AUTOSAR XML (schema 4-2-2)
package /ComponentTypes
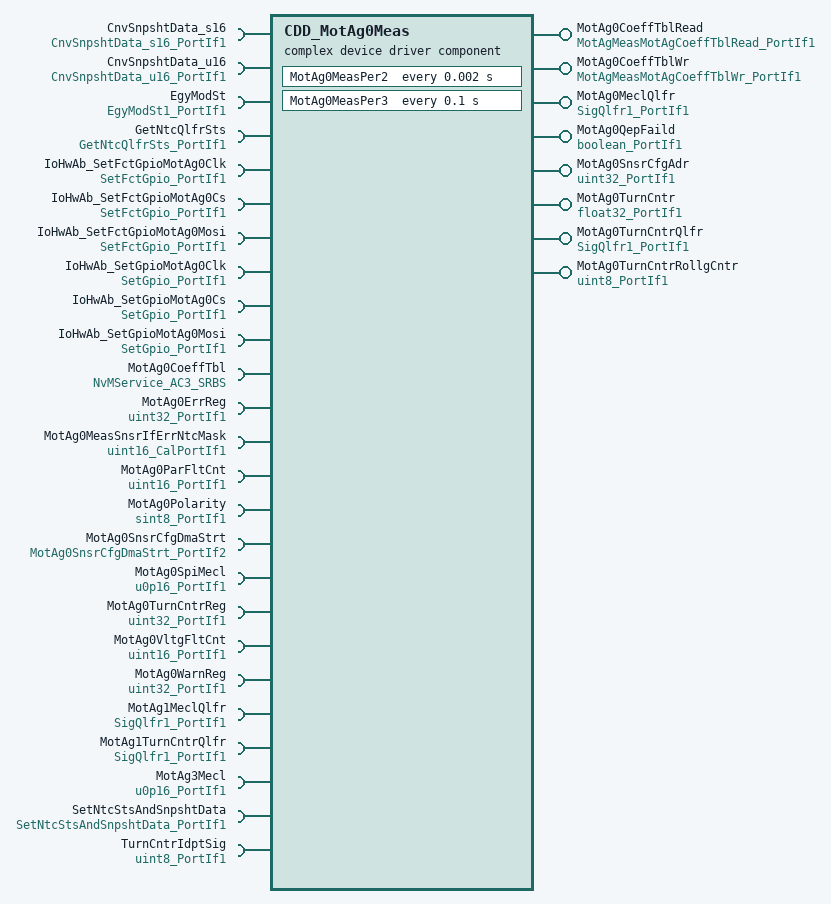
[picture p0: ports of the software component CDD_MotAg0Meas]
  complex device driver sw component type CDD_MotAg0Meas
    8 x provide port:
      MotAg0CoeffTblRead: server-com-spec{operation=Oper, queue-length=1}, provided-interface=MotAgMeasMotAgCoeffTblRead_PortIf1
      MotAg0CoeffTblWr: server-com-spec{operation=Oper, queue-length=1}, provided-interface=MotAgMeasMotAgCoeffTblWr_PortIf1
      MotAg0MeclQlfr: nonqueued-sender-com-spec{data-element=Val, init-value=0}, provided-interface=SigQlfr1_PortIf1
      MotAg0QepFaild: nonqueued-sender-com-spec{data-element=Logl, init-value=0}, provided-interface=boolean_PortIf1
      MotAg0SnsrCfgAdr: nonqueued-sender-com-spec{data-element=Val, init-value=0}, provided-interface=uint32_PortIf1
      MotAg0TurnCntr: nonqueued-sender-com-spec{data-element=Val, init-value=0}, provided-interface=float32_PortIf1
      MotAg0TurnCntrQlfr: nonqueued-sender-com-spec{data-element=Val, init-value=0}, provided-interface=SigQlfr1_PortIf1
      MotAg0TurnCntrRollgCntr: nonqueued-sender-com-spec{data-element=Val, init-value=0}, provided-interface=uint8_PortIf1
    25 x require port:
      CnvSnpshtData_s16: client-com-spec=Oper, required-interface=CnvSnpshtData_s16_PortIf1
      CnvSnpshtData_u16: client-com-spec=Oper, required-interface=CnvSnpshtData_u16_PortIf1
      EgyModSt: nonqueued-receiver-com-spec{data-element=Val, filter=data-filter-type=ALWAYS, init-value=0}, required-interface=EgyModSt1_PortIf1
      GetNtcQlfrSts: client-com-spec=Oper, required-interface=GetNtcQlfrSts_PortIf1
      IoHwAb_SetFctGpioMotAg0Clk: client-com-spec=Oper, required-interface=SetFctGpio_PortIf1
      IoHwAb_SetFctGpioMotAg0Cs: client-com-spec=Oper, required-interface=SetFctGpio_PortIf1
      IoHwAb_SetFctGpioMotAg0Mosi: client-com-spec=Oper, required-interface=SetFctGpio_PortIf1
      IoHwAb_SetGpioMotAg0Clk: client-com-spec=Oper, required-interface=SetGpio_PortIf1
      IoHwAb_SetGpioMotAg0Cs: client-com-spec=Oper, required-interface=SetGpio_PortIf1
      IoHwAb_SetGpioMotAg0Mosi: client-com-spec=Oper, required-interface=SetGpio_PortIf1
      MotAg0CoeffTbl: required-com-specs=[EraseBlock, GetErrorStatus, InvalidateNvBlock, ReadBlock, SetRamBlockStatus, WriteBlock], required-interface=NvMService_AC3_SRBS
      MotAg0ErrReg: nonqueued-receiver-com-spec{data-element=Val, filter=data-filter-type=ALWAYS, init-value=0}, required-interface=uint32_PortIf1
      MotAg0MeasSnsrIfErrNtcMask: parameter-require-com-spec{init-value=512, parameter=Val}, required-interface=uint16_CalPortIf1
      MotAg0ParFltCnt: nonqueued-receiver-com-spec{data-element=Val, filter=data-filter-type=ALWAYS, init-value=0}, required-interface=uint16_PortIf1
      MotAg0Polarity: nonqueued-receiver-com-spec{data-element=Val, filter=data-filter-type=ALWAYS, init-value=1}, required-interface=sint8_PortIf1
      MotAg0SnsrCfgDmaStrt: client-com-spec=Oper, required-interface=MotAg0SnsrCfgDmaStrt_PortIf2
      MotAg0SpiMecl: nonqueued-receiver-com-spec{data-element=Val, filter=data-filter-type=ALWAYS, init-value=0}, required-interface=u0p16_PortIf1
      MotAg0TurnCntrReg: nonqueued-receiver-com-spec{data-element=Val, filter=data-filter-type=ALWAYS, init-value=0}, required-interface=uint32_PortIf1
      MotAg0VltgFltCnt: nonqueued-receiver-com-spec{data-element=Val, filter=data-filter-type=ALWAYS, init-value=0}, required-interface=uint16_PortIf1
      MotAg0WarnReg: nonqueued-receiver-com-spec{data-element=Val, filter=data-filter-type=ALWAYS, init-value=0}, required-interface=uint32_PortIf1
      MotAg1MeclQlfr: nonqueued-receiver-com-spec{data-element=Val, filter=data-filter-type=ALWAYS, init-value=0}, required-interface=SigQlfr1_PortIf1
      MotAg1TurnCntrQlfr: nonqueued-receiver-com-spec{data-element=Val, filter=data-filter-type=ALWAYS, init-value=0}, required-interface=SigQlfr1_PortIf1
      MotAg3Mecl: nonqueued-receiver-com-spec{data-element=Val, filter=data-filter-type=ALWAYS, init-value=0}, required-interface=u0p16_PortIf1
      SetNtcStsAndSnpshtData: client-com-spec=Oper, required-interface=SetNtcStsAndSnpshtData_PortIf1
      TurnCntrIdptSig: nonqueued-receiver-com-spec{data-element=Val, filter=data-filter-type=ALWAYS, init-value=2}, required-interface=uint8_PortIf1
    behavior CDD_MotAg0Meas_InternalBehavior
      ar-typed-per-instance-memorys:
        30 x data, all with sw-calibration-access=READ-ONLY:
          dMotAg0MeasMotAg0Delta: type=u0p16  # Display variable holding difference between angle from QEP interface and angle from SPI bus
          dMotAg0MeasMotAg0RawAgReg: type=uint32  # Display variable for Motor Angle 0 Raw Angle Register
          dMotAg0MeasMotAg0RawErrReg: type=uint32  # Display variable for Motor Angle 0 Raw Error Register
          dMotAg0MeasMotAg0RawStsReg: type=uint32  # Display variable for Motor Angle 0 Raw status Register
          dMotAg0MeasMotAg0RawTurnCntrReg: type=uint32  # Display variable Motor Angle 0 Raw Turn Counter Register
          dMotAg0MeasMotAg0RawWarnReg: type=uint32  # Display variable for Motor Angle 0 Raw warning Register
          dMotAg0MeasMotAg0RtOffs: type=sint32  # Display variable of Motor Angle 0 Runtime Offset
          dMotAg0MeasPwrRstStsLtch: type=boolean
          MotAg0CoeffTbl: type=Ary1D_f32_26
          MotAg0CorrnTbl: type=Ary1D_sm5p12_128
          MotAg0InitOffs: type=sint32
          MotAg0InitOffsCntr: type=uint8
          MotAg0MeclRollgCntrPrev: type=uint8
          MotAg0ParFltCntNtcPrev: type=uint16
          MotAg0ParFltCntPrev: type=uint16
          MotAg0PrevSpiMecl: type=u0p16
          MotAg0PrevTCUpd: type=sint16
          MotAg0QepFaildCntr: type=uint32
          MotAg0QepFaildPrev: type=boolean
          MotAg0RawMeclPrev: type=u0p16
          MotAg0SnsrCfg: type=uint32
          MotAg0TurnCntrParFltCntNtcPrev: type=uint16
          MotAg0TurnCntrParFltCntPrev: type=uint16
          MotAg0TurnCntrPrev: type=sint16
          MotAg0TurnCntrRollgCntrPrev: type=uint8
          MotAg0VltgFltCntNtcPrev: type=uint16
          MotAg0VltgFltCntPrev: type=uint16
          MotAgCtrlRegCfg: type=uint8
          MotAgMecl0Polarity: type=sint8
          MotAgSnsrCfgSt: type=MotAgSnsrCfgSt1
      operation invoked event OIT_MotAg0CoeffTblRead_Oper_MotAg0CoeffTblRead_Oper: start-on-event=MotAg0CoeffTblRead_Oper, operation=MotAg0CoeffTblRead.Oper
      operation invoked event OIT_MotAg0CoeffTblWr_Oper_MotAg0CoeffTblWr_Oper: start-on-event=MotAg0CoeffTblWr_Oper, operation=MotAg0CoeffTblWr.Oper
      init event CDD_MotAg0Meas_InitEvent: start-on-event=MotAg0MeasInit1
      timing event TMT_MotAg0MeasPer2: start-on-event=MotAg0MeasPer2, period=0.002
      timing event TMT_MotAg0MeasPer3: start-on-event=MotAg0MeasPer3, period=0.1
      explicit-inter-runnable-variables:
        data MotAg0Qlfr: type=SigQlfr1, init-value=0
        data TurnCntr0Qlfr: type=SigQlfr1, init-value=0
      port-api-options:
        enable-take-address=false, error-handling=NO-TRANSFORMER-ERROR-HANDLING, indirect-api=false, port=CnvSnpshtData_s16
        enable-take-address=false, error-handling=NO-TRANSFORMER-ERROR-HANDLING, indirect-api=false, port=CnvSnpshtData_u16
        enable-take-address=false, error-handling=NO-TRANSFORMER-ERROR-HANDLING, indirect-api=false, port=EgyModSt
        enable-take-address=false, error-handling=NO-TRANSFORMER-ERROR-HANDLING, indirect-api=false, port=GetNtcQlfrSts
        enable-take-address=false, error-handling=NO-TRANSFORMER-ERROR-HANDLING, indirect-api=false, port=MotAg0CoeffTbl
        enable-take-address=false, error-handling=NO-TRANSFORMER-ERROR-HANDLING, indirect-api=false, port=MotAg0CoeffTblRead
        enable-take-address=false, error-handling=NO-TRANSFORMER-ERROR-HANDLING, indirect-api=false, port=MotAg0CoeffTblWr
        enable-take-address=false, error-handling=NO-TRANSFORMER-ERROR-HANDLING, indirect-api=false, port=MotAg0ErrReg
        enable-take-address=false, error-handling=NO-TRANSFORMER-ERROR-HANDLING, indirect-api=false, port=MotAg0MeasSnsrIfErrNtcMask
        enable-take-address=false, error-handling=NO-TRANSFORMER-ERROR-HANDLING, indirect-api=false, port=MotAg0MeclQlfr
        enable-take-address=false, error-handling=NO-TRANSFORMER-ERROR-HANDLING, indirect-api=false, port=MotAg0ParFltCnt
        enable-take-address=false, error-handling=NO-TRANSFORMER-ERROR-HANDLING, indirect-api=false, port=MotAg0Polarity
        enable-take-address=false, error-handling=NO-TRANSFORMER-ERROR-HANDLING, indirect-api=false, port=MotAg0QepFaild
        enable-take-address=false, error-handling=NO-TRANSFORMER-ERROR-HANDLING, indirect-api=false, port=MotAg0SnsrCfgAdr
        enable-take-address=false, error-handling=NO-TRANSFORMER-ERROR-HANDLING, indirect-api=false, port=MotAg0SnsrCfgDmaStrt
        enable-take-address=false, error-handling=NO-TRANSFORMER-ERROR-HANDLING, indirect-api=false, port=MotAg0SpiMecl
        enable-take-address=false, error-handling=NO-TRANSFORMER-ERROR-HANDLING, indirect-api=false, port=MotAg0TurnCntr
        enable-take-address=false, error-handling=NO-TRANSFORMER-ERROR-HANDLING, indirect-api=false, port=MotAg0TurnCntrQlfr
        enable-take-address=false, error-handling=NO-TRANSFORMER-ERROR-HANDLING, indirect-api=false, port=MotAg0TurnCntrReg
        enable-take-address=false, error-handling=NO-TRANSFORMER-ERROR-HANDLING, indirect-api=false, port=MotAg0TurnCntrRollgCntr
        enable-take-address=false, error-handling=NO-TRANSFORMER-ERROR-HANDLING, indirect-api=false, port=MotAg0VltgFltCnt
        enable-take-address=false, error-handling=NO-TRANSFORMER-ERROR-HANDLING, indirect-api=false, port=MotAg0WarnReg
        enable-take-address=false, error-handling=NO-TRANSFORMER-ERROR-HANDLING, indirect-api=false, port=MotAg1MeclQlfr
        enable-take-address=false, error-handling=NO-TRANSFORMER-ERROR-HANDLING, indirect-api=false, port=MotAg1TurnCntrQlfr
        enable-take-address=false, error-handling=NO-TRANSFORMER-ERROR-HANDLING, indirect-api=false, port=MotAg3Mecl
        enable-take-address=false, error-handling=NO-TRANSFORMER-ERROR-HANDLING, indirect-api=false, port=SetNtcStsAndSnpshtData
        enable-take-address=false, error-handling=NO-TRANSFORMER-ERROR-HANDLING, indirect-api=false, port=TurnCntrIdptSig
      5 x runnable:
        MotAg0CoeffTblRead_Oper
        MotAg0CoeffTblWr_Oper
          sync call SC_MotAg0CoeffTbl_SetRamBlockStatus: operation=MotAg0CoeffTbl.SetRamBlockStatus, timeout=0
        MotAg0MeasInit1
          data-receive-point-by-arguments:
            access REC_MotAg0Polarity_Val: accessed-variable=MotAg0Polarity.Val
          data-send-points:
            access SEND_MotAg0SnsrCfgAdr_Val: accessed-variable=MotAg0SnsrCfgAdr.Val
          7 x sync call, all with timeout=0:
            SC_IoHwAb_SetFctGpioMotAg0Clk_Oper: operation=IoHwAb_SetFctGpioMotAg0Clk.Oper
            SC_IoHwAb_SetFctGpioMotAg0Cs_Oper: operation=IoHwAb_SetFctGpioMotAg0Cs.Oper
            SC_IoHwAb_SetFctGpioMotAg0Mosi_Oper: operation=IoHwAb_SetFctGpioMotAg0Mosi.Oper
            SC_IoHwAb_SetGpioMotAg0Clk_Oper: operation=IoHwAb_SetGpioMotAg0Clk.Oper
            SC_IoHwAb_SetGpioMotAg0Cs_Oper: operation=IoHwAb_SetGpioMotAg0Cs.Oper
            SC_IoHwAb_SetGpioMotAg0Mosi_Oper: operation=IoHwAb_SetGpioMotAg0Mosi.Oper
            SC_MotAg0CoeffTbl_GetErrorStatus: operation=MotAg0CoeffTbl.GetErrorStatus
        MotAg0MeasPer2
          data-receive-point-by-arguments:
            8 x access:
              REC_MotAg0ErrReg_Val: accessed-variable=MotAg0ErrReg.Val
              REC_MotAg0ParFltCnt_Val: accessed-variable=MotAg0ParFltCnt.Val
              REC_MotAg0Polarity_Val: accessed-variable=MotAg0Polarity.Val
              REC_MotAg0SpiMecl_Val: accessed-variable=MotAg0SpiMecl.Val
              REC_MotAg0TurnCntrReg_Val: accessed-variable=MotAg0TurnCntrReg.Val
              REC_MotAg0VltgFltCnt_Val: accessed-variable=MotAg0VltgFltCnt.Val
              REC_MotAg0WarnReg_Val: accessed-variable=MotAg0WarnReg.Val
              REC_MotAg3Mecl_Val: accessed-variable=MotAg3Mecl.Val
          data-send-points:
            5 x access:
              SEND_MotAg0MeclQlfr_Val: accessed-variable=MotAg0MeclQlfr.Val
              SEND_MotAg0QepFaild_Logl: accessed-variable=MotAg0QepFaild.Logl
              SEND_MotAg0TurnCntr_Val: accessed-variable=MotAg0TurnCntr.Val
              SEND_MotAg0TurnCntrQlfr_Val: accessed-variable=MotAg0TurnCntrQlfr.Val
              SEND_MotAg0TurnCntrRollgCntr_Val: accessed-variable=MotAg0TurnCntrRollgCntr.Val
          4 x sync call, all with timeout=0:
            SC_CnvSnpshtData_s16_Oper: operation=CnvSnpshtData_s16.Oper
            SC_CnvSnpshtData_u16_Oper: operation=CnvSnpshtData_u16.Oper
            SC_GetNtcQlfrSts_Oper: operation=GetNtcQlfrSts.Oper
            SC_SetNtcStsAndSnpshtData_Oper: operation=SetNtcStsAndSnpshtData.Oper
          written-local-variables:
            access WRITE_MotAg0Qlfr: accessed-variable=MotAg0Qlfr
            access WRITE_TurnCntr0Qlfr: accessed-variable=TurnCntr0Qlfr
        MotAg0MeasPer3
          data-receive-point-by-arguments:
            4 x access:
              REC_EgyModSt_Val: accessed-variable=EgyModSt.Val
              REC_MotAg1MeclQlfr_Val: accessed-variable=MotAg1MeclQlfr.Val
              REC_MotAg1TurnCntrQlfr_Val: accessed-variable=MotAg1TurnCntrQlfr.Val
              REC_TurnCntrIdptSig_Val: accessed-variable=TurnCntrIdptSig.Val
          read-local-variables:
            access READ_MotAg0Qlfr: accessed-variable=MotAg0Qlfr
            access READ_TurnCntr0Qlfr: accessed-variable=TurnCntr0Qlfr
          sync call SC_MotAg0SnsrCfgDmaStrt_Oper: operation=MotAg0SnsrCfgDmaStrt.Oper, timeout=0
      swc service dependency NvmMotAg0CoeffTbl: assigned-datas=role-based-data-assignment={role=ramBlock, used-data-element=MotAg0CoeffTbl}, assigned-ports=role-based-port-assignment={port-prototype=MotAg0CoeffTbl, role=NvMService_AC3_SRBS}
        service-needs:
          nv block needs NvmMotAg0CoeffTbl: n-data-sets=0, ram-block-status-control=API, readonly=false, reliability=ERROR-DETECTION, resistant-to-changed-sw=true, restore-at-start=true, store-at-shutdown=true, write-only-once=false, writing-frequency=0, writing-priority=LOW
      shared-parameters:
        parameter data prototype MotAg0CoeffTblDft: sw-calibration-access=READ-WRITE, type=Ary1D_f32_26, init-value=26 x 0
  swc implementation CDD_MotAg0Meas_Implementation: behavior=CDD_MotAg0Meas_InternalBehavior
    code-descriptors:
      code Default: artifact-descriptors=autosar-engineering-object={short-label=Default, category=SWSRC}
